# STM32G4xx register map
File version: 1.3
CPU: CM4 r0p1, little endian, MPU, FPU, 4 interrupt priority bits
Registers are 32-bit, read-write, reset 0x0 unless marked. A register's access mark holds for its fields unless they carry their own. Offsets are from the block's base; [hi:lo] are bit positions; {n}, {i} and the like mark numbered series.

## TIMER1 — Advanced-timers
Base 0x40012C00
Same registers: TIMER8 0x40013400, TIM20 0x40015000
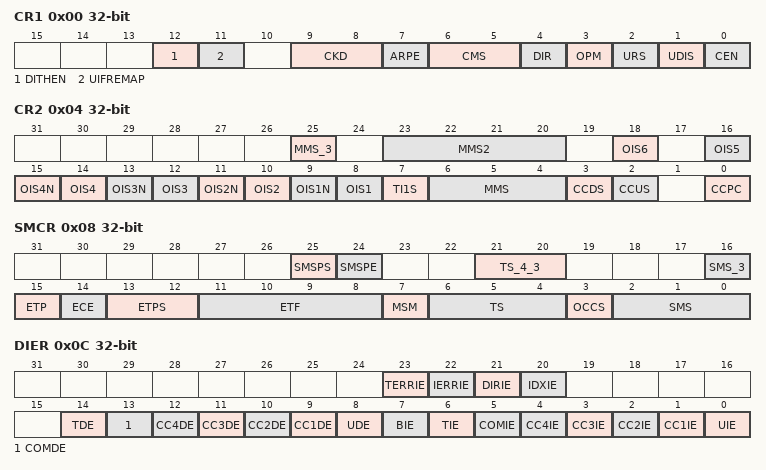
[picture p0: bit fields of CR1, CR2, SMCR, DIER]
0x00 CR1 — control register 1
  [12] DITHEN — Dithering Enable
  [11] UIFREMAP — UIF status bit remapping
  [9:8] CKD — Clock division
  [7] ARPE — Auto-reload preload enable
  [6:5] CMS — Center-aligned mode selection
  [4] DIR — Direction
  [3] OPM — One-pulse mode
  [2] URS — Update request source
  [1] UDIS — Update disable
  [0] CEN — Counter enable
0x04 CR2 — control register 2
  [25] MMS_3 — Master mode selection - bit 3
  [23:20] MMS2 — Master mode selection 2
  [18] OIS6 — Output Idle state 6 (OC6 output)
  [16] OIS5 — Output Idle state 5 (OC5 output)
  [15] OIS4N — Output Idle state 4 (OC4N output)
  [2n+6] OIS{n} (n=1..4) — Output Idle state {n}
  [13] OIS3N — Output Idle state 3
  [11] OIS2N — Output Idle state 2
  [9] OIS1N — Output Idle state 1
  [7] TI1S — TI1 selection
  [6:4] MMS — Master mode selection
  [3] CCDS — Capture/compare DMA selection
  [2] CCUS — Capture/compare control update selection
  [0] CCPC — Capture/compare preloaded control
0x08 SMCR — slave mode control register
  [25] SMSPS — SMS Preload Source
  [24] SMSPE — SMS Preload Enable
  [21:20] TS_4_3 — Trigger selection - bit 4:3
  [16] SMS_3 — Slave mode selection - bit 3
  [15] ETP — External trigger polarity
  [14] ECE — External clock enable
  [13:12] ETPS — External trigger prescaler
  [11:8] ETF — External trigger filter
  [7] MSM — Master/Slave mode
  [6:4] TS — Trigger selection
  [3] OCCS — OCREF clear selection
  [2:0] SMS — Slave mode selection
0x0C DIER — DMA/Interrupt enable register
  [23] TERRIE — Transition Error interrupt enable
  [22] IERRIE — Index Error interrupt enable
  [21] DIRIE — Direction Change interrupt enable
  [20] IDXIE — Index interrupt enable
  [14] TDE — Trigger DMA request enable
  [13] COMDE — COM DMA request enable
  [n+8] CC{n}DE (n=1..4) — Capture/Compare {n} DMA request enable
  [8] UDE — Update DMA request enable
  [7] BIE — Break interrupt enable
  [6] TIE — Trigger interrupt enable
  [5] COMIE — COM interrupt enable
  [n] CC{n}IE (n=1..4) — Capture/Compare {n} interrupt enable
  [0] UIE — Update interrupt enable
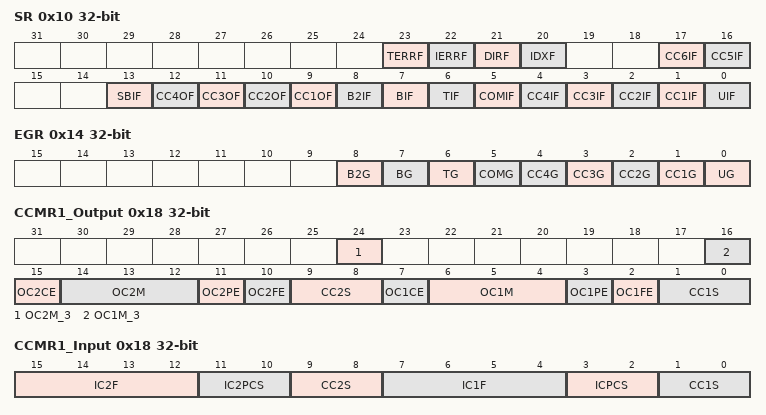
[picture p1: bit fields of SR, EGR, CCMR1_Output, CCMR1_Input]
0x10 SR — status register
  [23] TERRF — Transition Error interrupt flag
  [22] IERRF — Index Error interrupt flag
  [21] DIRF — Direction Change interrupt flag
  [20] IDXF — Index interrupt flag
  [17] CC6IF — Compare 6 interrupt flag
  [16] CC5IF — Compare 5 interrupt flag
  [13] SBIF — System Break interrupt flag
  [12] CC4OF — Capture/Compare 4 overcapture flag
  [11] CC3OF — Capture/Compare 3 overcapture flag
  [10] CC2OF — Capture/compare 2 overcapture flag
  [9] CC1OF — Capture/Compare 1 overcapture flag
  [8] B2IF — Break 2 interrupt flag
  [7] BIF — Break interrupt flag
  [6] TIF — Trigger interrupt flag
  [5] COMIF — COM interrupt flag
  [4] CC4IF — Capture/Compare 4 interrupt flag
  [3] CC3IF — Capture/Compare 3 interrupt flag
  [2] CC2IF — Capture/Compare 2 interrupt flag
  [1] CC1IF — Capture/compare 1 interrupt flag
  [0] UIF — Update interrupt flag
0x14 EGR wo — event generation register
  [8] B2G — Break 2 generation
  [7] BG — Break generation
  [6] TG — Trigger generation
  [5] COMG — Capture/Compare control update generation
  [n] CC{n}G (n=1..4) — Capture/compare {n} generation
  [0] UG — Update generation
0x18 CCMR1_Output — capture/compare mode register 1 (output mode)
  [24] OC2M_3 — Output Compare 2 mode - bit 3
  [16] OC1M_3 — Output Compare 1 mode - bit 3
  [15] OC2CE — Output Compare 2 clear enable
  [14:12] OC2M — Output Compare 2 mode
  [11] OC2PE — Output Compare 2 preload enable
  [10] OC2FE — Output Compare 2 fast enable
  [9:8] CC2S — Capture/Compare 2 selection
  [7] OC1CE — Output Compare 1 clear enable
  [6:4] OC1M — Output Compare 1 mode
  [3] OC1PE — Output Compare 1 preload enable
  [2] OC1FE — Output Compare 1 fast enable
  [1:0] CC1S — Capture/Compare 1 selection
0x18 CCMR1_Input (alternate view of CCMR1_Output) — capture/compare mode register 1 (input mode)
  [15:12] IC2F — Input capture 2 filter
  [11:10] IC2PCS — Input capture 2 prescaler
  [9:8] CC2S — Capture/Compare 2 selection
  [7:4] IC1F — Input capture 1 filter
  [3:2] ICPCS — Input capture 1 prescaler
  [1:0] CC1S — Capture/Compare 1 selection
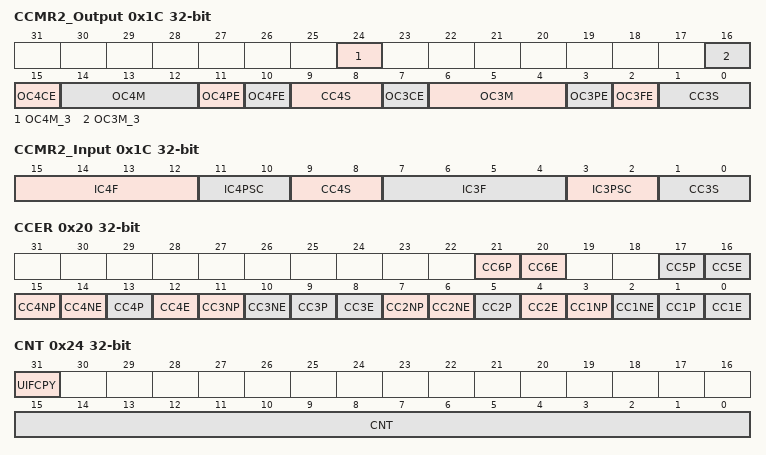
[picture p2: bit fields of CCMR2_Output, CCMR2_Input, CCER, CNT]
0x1C CCMR2_Output — capture/compare mode register 2 (output mode)
  [24] OC4M_3 — Output Compare 4 mode - bit 3
  [16] OC3M_3 — Output Compare 3 mode - bit 3
  [15] OC4CE — Output compare 4 clear enable
  [14:12] OC4M — Output compare 4 mode
  [11] OC4PE — Output compare 4 preload enable
  [10] OC4FE — Output compare 4 fast enable
  [9:8] CC4S — Capture/Compare 4 selection
  [7] OC3CE — Output compare 3 clear enable
  [6:4] OC3M — Output compare 3 mode
  [3] OC3PE — Output compare 3 preload enable
  [2] OC3FE — Output compare 3 fast enable
  [1:0] CC3S — Capture/Compare 3 selection
0x1C CCMR2_Input (alternate view of CCMR2_Output) — capture/compare mode register 2 (input mode)
  [15:12] IC4F — Input capture 4 filter
  [11:10] IC4PSC — Input capture 4 prescaler
  [9:8] CC4S — Capture/Compare 4 selection
  [7:4] IC3F — Input capture 3 filter
  [3:2] IC3PSC — Input capture 3 prescaler
  [1:0] CC3S — Capture/compare 3 selection
0x20 CCER — capture/compare enable register
  [21] CC6P — Capture/Compare 6 output polarity
  [4n-4] CC{n}E (n=1..6) — Capture/Compare {n} output enable
  [17] CC5P — Capture/Compare 5 output polarity
  [15] CC4NP — Capture/Compare 4 complementary output polarity
  [4n-2] CC{n}NE (n=1..4) — Capture/Compare {n} complementary output enable
  [13] CC4P — Capture/Compare 3 output Polarity
  [11] CC3NP — Capture/Compare 3 output Polarity
  [9] CC3P — Capture/Compare 3 output Polarity
  [7] CC2NP — Capture/Compare 2 output Polarity
  [5] CC2P — Capture/Compare 2 output Polarity
  [3] CC1NP — Capture/Compare 1 output Polarity
  [1] CC1P — Capture/Compare 1 output Polarity
0x24 CNT access per field — counter
  [31] UIFCPY ro
  [15:0] CNT rw — counter value
0x28 PSC — prescaler
  [15:0] PSC — Prescaler value
0x2C ARR reset 0xFFFF — auto-reload register
  [15:0] ARR — Auto-reload value
0x30 RCR — repetition counter register
  [15:0] REP — Repetition counter value
0x34 CCR1 — capture/compare register 1
  [15:0] CCR1 — Capture/Compare 1 value
0x38 CCR2 — capture/compare register 2
  [15:0] CCR2 — Capture/Compare 2 value
0x3C CCR3 — capture/compare register 3
  [15:0] CCR3 — Capture/Compare value
0x40 CCR4 — capture/compare register 4
  [15:0] CCR4 — Capture/Compare value
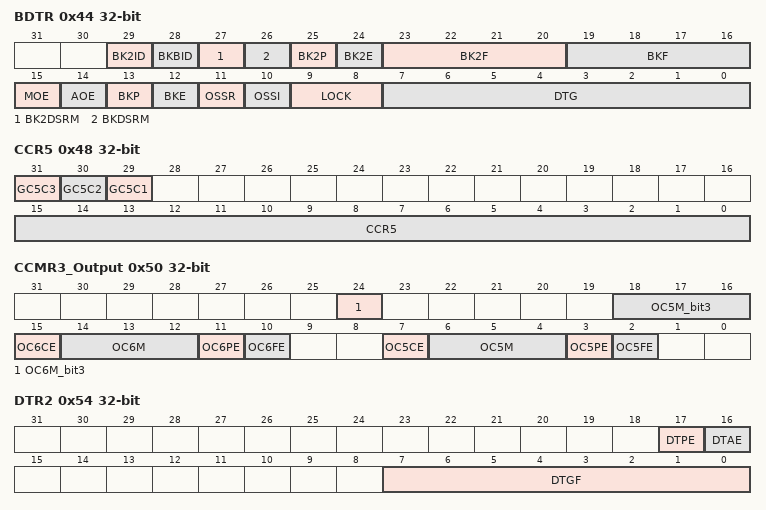
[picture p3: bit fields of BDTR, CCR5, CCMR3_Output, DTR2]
0x44 BDTR — break and dead-time register
  [29] BK2ID
  [28] BKBID
  [27] BK2DSRM
  [26] BKDSRM
  [25] BK2P — Break 2 polarity
  [24] BK2E — Break 2 Enable
  [23:20] BK2F — Break 2 filter
  [19:16] BKF — Break filter
  [15] MOE — Main output enable
  [14] AOE — Automatic output enable
  [13] BKP — Break polarity
  [12] BKE — Break enable
  [11] OSSR — Off-state selection for Run mode
  [10] OSSI — Off-state selection for Idle mode
  [9:8] LOCK — Lock configuration
  [7:0] DTG — Dead-time generator setup
0x48 CCR5 — capture/compare register 4
  [31] GC5C3 — Group Channel 5 and Channel 3
  [30] GC5C2 — Group Channel 5 and Channel 2
  [29] GC5C1 — Group Channel 5 and Channel 1
  [15:0] CCR5 — Capture/Compare value
0x4C CCR6 — capture/compare register 4
  [15:0] CCR6 — Capture/Compare value
0x50 CCMR3_Output — capture/compare mode register 2 (output mode)
  [24] OC6M_bit3 — Output Compare 6 mode bit 3
  [18:16] OC5M_bit3 — Output Compare 5 mode bit 3
  [15] OC6CE — Output compare 6 clear enable
  [14:12] OC6M — Output compare 6 mode
  [11] OC6PE — Output compare 6 preload enable
  [10] OC6FE — Output compare 6 fast enable
  [7] OC5CE — Output compare 5 clear enable
  [6:4] OC5M — Output compare 5 mode
  [3] OC5PE — Output compare 5 preload enable
  [2] OC5FE — Output compare 5 fast enable
0x54 DTR2 — timer Deadtime Register 2
  [17] DTPE — Deadtime Preload Enable
  [16] DTAE — Deadtime Asymmetric Enable
  [7:0] DTGF — Dead-time falling edge generator setup
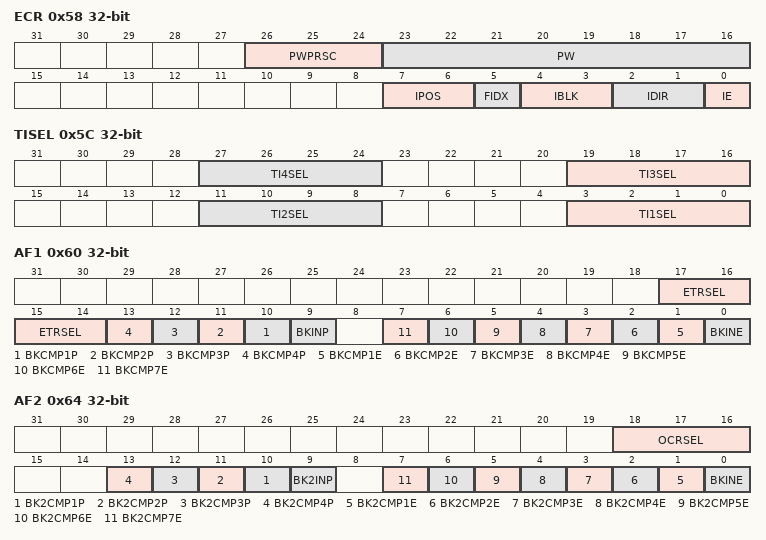
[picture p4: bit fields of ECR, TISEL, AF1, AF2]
0x58 ECR — DMA control register
  [26:24] PWPRSC — Pulse Width prescaler
  [23:16] PW — Pulse width
  [7:6] IPOS — Index Positioning
  [5] FIDX — First Index
  [4:3] IBLK — Index Blanking
  [2:1] IDIR — Index Direction
  [0] IE — Index Enable
0x5C TISEL — TIM timer input selection register
  [8n-5:8n-8] TI{n}SEL (n=1..4) — TI{n}[0] to TI{n}[15] input selection
0x60 AF1 — TIM alternate function option register 1
  [17:14] ETRSEL — ETR source selection
  [n+9] BKCMP{n}P (n=1..4) — BRK COMP{n} input polarity
  [9] BKINP — BRK BKIN input polarity
  [n] BKCMP{n}E (n=1..7) — BRK COMP{n} enable
  [0] BKINE — BRK BKIN input enable
0x64 AF2 — TIM alternate function option register 2
  [18:16] OCRSEL — OCREF_CLR source selection
  [n+9] BK2CMP{n}P (n=1..4) — BRK2 COMP{n} input polarity
  [9] BK2INP — BRK2 BKIN input polarity
  [n] BK2CMP{n}E (n=1..7) — BRK2 COMP{n} enable
  [0] BKINE — BRK BKIN input enable
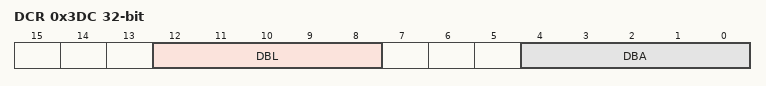
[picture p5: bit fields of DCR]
0x3DC DCR — control register
  [12:8] DBL — DMA burst length
  [4:0] DBA — DMA base address
0x3E0 DMAR — DMA address for full transfer
  [31:0] DMAB — DMA register for burst accesses

## TIMER2 — Advanced-timers
Base 0x40000000
Same registers: TIMER3 0x40000400, TIMER4 0x40000800, TIMER5 0x40000C00
Registers as TIMER1; these are added or differ:
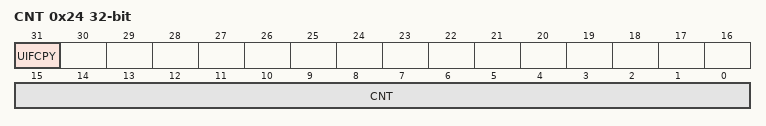
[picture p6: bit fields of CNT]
0x24 CNT — counter
  [31] UIFCPY
  [15:0] CNT — counter value
0x2C ARR reset 0xFFFFFFFF — auto-reload register
  [15:0] ARR — Auto-reload value
